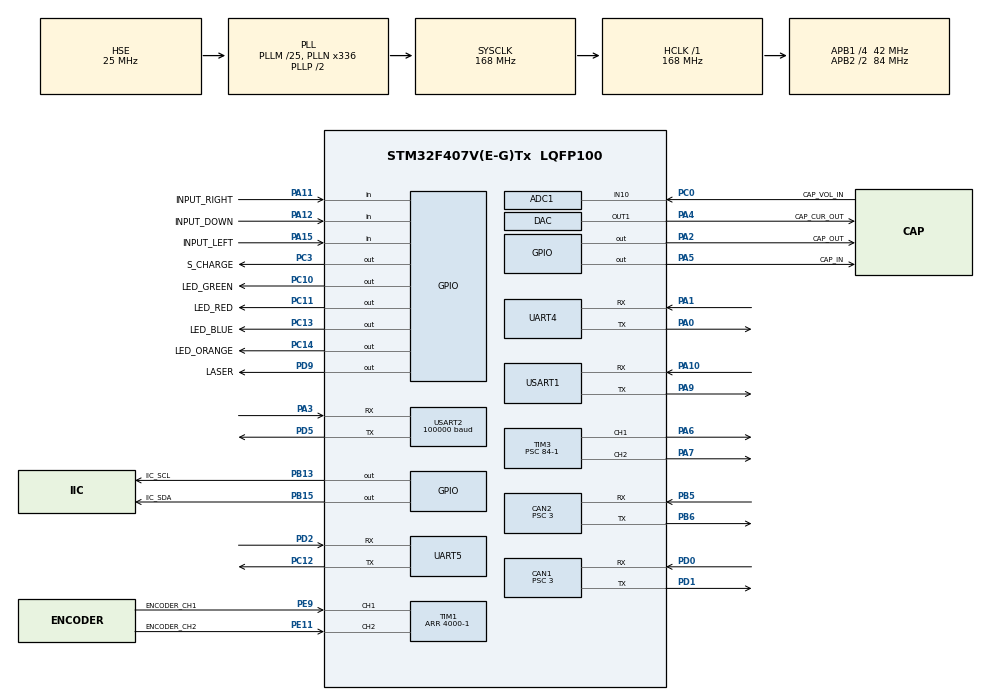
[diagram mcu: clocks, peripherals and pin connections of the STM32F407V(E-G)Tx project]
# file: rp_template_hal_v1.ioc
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ADC1.Channel-0\#ChannelRegularConversion=ADC_CHANNEL_10
ADC1.NbrOfConversionFlag=1
ADC1.Rank-0\#ChannelRegularConversion=1
ADC1.SamplingTime-0\#ChannelRegularConversion=ADC_SAMPLETIME_3CYCLES
ADC1.master=1
CAN1.ABOM=ENABLE
CAN1.AWUM=ENABLE
CAN1.BS1=CAN_BS1_9TQ
CAN1.BS2=CAN_BS2_4TQ
CAN1.CalculateBaudRate=1000000
CAN1.CalculateTimeBit=999.99
CAN1.CalculateTimeQuantum=71.42857142857143
CAN1.NART=ENABLE
CAN1.Prescaler=3
CAN1.TXFP=ENABLE
CAN2.ABOM=ENABLE
CAN2.AWUM=ENABLE
CAN2.BS1=CAN_BS1_9TQ
CAN2.BS2=CAN_BS2_4TQ
CAN2.CalculateBaudRate=1000000
CAN2.CalculateTimeBit=999.99
CAN2.CalculateTimeQuantum=71.42857142857143
CAN2.NART=ENABLE
CAN2.Prescaler=3
CAN2.TXFP=ENABLE
DAC.DAC_OutputBuffer=DAC_OUTPUTBUFFER_DISABLE
Dma.Request0=UART5_RX
Dma.Request1=USART1_RX
Dma.Request2=UART4_RX
Dma.Request3=USART2_RX
Dma.Request4=USART1_TX
Dma.Request5=UART4_TX
Dma.UART4_RX.2.Direction=DMA_PERIPH_TO_MEMORY
Dma.UART4_RX.2.FIFOMode=DMA_FIFOMODE_DISABLE
Dma.UART4_RX.2.Instance=DMA1_Stream2
Dma.UART4_RX.2.MemDataAlignment=DMA_MDATAALIGN_BYTE
Dma.UART4_RX.2.MemInc=DMA_MINC_ENABLE
Dma.UART4_RX.2.Mode=DMA_CIRCULAR
Dma.UART4_RX.2.PeriphDataAlignment=DMA_PDATAALIGN_BYTE
Dma.UART4_RX.2.PeriphInc=DMA_PINC_DISABLE
Dma.UART4_RX.2.Priority=DMA_PRIORITY_HIGH
Dma.UART4_TX.5.Direction=DMA_MEMORY_TO_PERIPH
Dma.UART4_TX.5.FIFOMode=DMA_FIFOMODE_DISABLE
Dma.UART4_TX.5.Instance=DMA1_Stream4
Dma.UART4_TX.5.MemDataAlignment=DMA_MDATAALIGN_BYTE
Dma.UART4_TX.5.MemInc=DMA_MINC_ENABLE
Dma.UART4_TX.5.Mode=DMA_NORMAL
Dma.UART4_TX.5.PeriphDataAlignment=DMA_PDATAALIGN_BYTE
Dma.UART4_TX.5.PeriphInc=DMA_PINC_DISABLE
Dma.UART4_TX.5.Priority=DMA_PRIORITY_HIGH
Dma.UART5_RX.0.Direction=DMA_PERIPH_TO_MEMORY
Dma.UART5_RX.0.FIFOMode=DMA_FIFOMODE_DISABLE
Dma.UART5_RX.0.Instance=DMA1_Stream0
Dma.UART5_RX.0.MemDataAlignment=DMA_MDATAALIGN_BYTE
Dma.UART5_RX.0.MemInc=DMA_MINC_ENABLE
Dma.UART5_RX.0.Mode=DMA_CIRCULAR
Dma.UART5_RX.0.PeriphDataAlignment=DMA_PDATAALIGN_BYTE
Dma.UART5_RX.0.PeriphInc=DMA_PINC_DISABLE
Dma.UART5_RX.0.Priority=DMA_PRIORITY_VERY_HIGH
Dma.USART1_RX.1.Direction=DMA_PERIPH_TO_MEMORY
Dma.USART1_RX.1.FIFOMode=DMA_FIFOMODE_DISABLE
Dma.USART1_RX.1.Instance=DMA2_Stream2
Dma.USART1_RX.1.MemDataAlignment=DMA_MDATAALIGN_BYTE
Dma.USART1_RX.1.MemInc=DMA_MINC_ENABLE
Dma.USART1_RX.1.Mode=DMA_CIRCULAR
Dma.USART1_RX.1.PeriphDataAlignment=DMA_PDATAALIGN_BYTE
Dma.USART1_RX.1.PeriphInc=DMA_PINC_DISABLE
Dma.USART1_RX.1.Priority=DMA_PRIORITY_HIGH
Dma.USART1_TX.4.Direction=DMA_MEMORY_TO_PERIPH
Dma.USART1_TX.4.FIFOMode=DMA_FIFOMODE_DISABLE
Dma.USART1_TX.4.Instance=DMA2_Stream7
Dma.USART1_TX.4.MemDataAlignment=DMA_MDATAALIGN_BYTE
Dma.USART1_TX.4.MemInc=DMA_MINC_ENABLE
Dma.USART1_TX.4.Mode=DMA_NORMAL
Dma.USART1_TX.4.PeriphDataAlignment=DMA_PDATAALIGN_BYTE
Dma.USART1_TX.4.PeriphInc=DMA_PINC_DISABLE
Dma.USART1_TX.4.Priority=DMA_PRIORITY_HIGH
Dma.USART2_RX.3.Direction=DMA_PERIPH_TO_MEMORY
Dma.USART2_RX.3.FIFOMode=DMA_FIFOMODE_DISABLE
Dma.USART2_RX.3.Instance=DMA1_Stream5
Dma.USART2_RX.3.MemDataAlignment=DMA_MDATAALIGN_BYTE
Dma.USART2_RX.3.MemInc=DMA_MINC_ENABLE
Dma.USART2_RX.3.Mode=DMA_CIRCULAR
Dma.USART2_RX.3.PeriphDataAlignment=DMA_PDATAALIGN_BYTE
Dma.USART2_RX.3.PeriphInc=DMA_PINC_DISABLE
Dma.USART2_RX.3.Priority=DMA_PRIORITY_VERY_HIGH
FREERTOS.Tasks01=MonitorTask,0,256,StartMonitorTask,As weak,NULL,Dynamic,NULL,NULL;SystemTask,0,128,StartSystemTask,As external,NULL,Dynamic,NULL,NULL;SendTask,-1,256,StartSendTask,As external,NULL,Dynamic,NULL,NULL;GimbalTask,2,256,StartGimbalTask,As external,NULL,Dynamic,NULL,NULL;ChassisTask,2,256,StartChassisTask,As external,NULL,Dynamic,NULL,NULL;FireTask,2,256,StartFireTask,As external,NULL,Dynamic,NULL,NULL;VisionTask,2,256,StartVisionTask,As external,NULL,Dynamic,NULL,NULL;ControlTask,2,256,StartControlTask,As external,NULL,Dynamic,NULL,NULL
IWDG.Prescaler=IWDG_PRESCALER_16
Mcu.Family=STM32F4
Mcu.Name=STM32F407V(E-G)Tx
Mcu.Package=LQFP100
NVIC.CAN1_RX0_IRQn=true\:5\:0\:true\:false\:true\:true\:true\:true
NVIC.CAN2_RX0_IRQn=true\:5\:0\:true\:false\:true\:true\:true\:true
NVIC.DMA1_Stream0_IRQn=true\:5\:0\:false\:false\:true\:true\:false\:true
NVIC.DMA1_Stream2_IRQn=true\:5\:0\:false\:false\:true\:true\:false\:true
NVIC.DMA1_Stream4_IRQn=true\:5\:0\:false\:false\:true\:true\:false\:true
NVIC.DMA1_Stream5_IRQn=true\:5\:0\:false\:false\:true\:true\:false\:true
NVIC.DMA2_Stream2_IRQn=true\:5\:0\:false\:false\:true\:true\:false\:true
NVIC.DMA2_Stream7_IRQn=true\:5\:0\:false\:false\:true\:true\:false\:true
NVIC.PriorityGroup=NVIC_PRIORITYGROUP_4
NVIC.TIM2_IRQn=true\:15\:0\:true\:false\:true\:false\:false\:true
NVIC.TimeBase=TIM2_IRQn
NVIC.TimeBaseIP=TIM2
NVIC.UART4_IRQn=true\:5\:0\:true\:false\:true\:true\:true\:true
NVIC.UART5_IRQn=true\:5\:0\:true\:false\:true\:true\:true\:true
NVIC.USART1_IRQn=true\:5\:0\:true\:false\:true\:true\:true\:true
NVIC.USART2_IRQn=true\:5\:0\:true\:false\:true\:true\:true\:true
PA0-WKUP.Mode=Asynchronous
PA0-WKUP.Signal=UART4_TX
PA1.Mode=Asynchronous
PA1.Signal=UART4_RX
PA10.Mode=Asynchronous
PA10.Signal=USART1_RX
PA11.GPIO_Label=INPUT_RIGHT
PA11.GPIO_PuPd=GPIO_PULLUP
PA11.Signal=GPIO_Input
PA12.GPIO_Label=INPUT_DOWN
PA12.GPIO_PuPd=GPIO_PULLUP
PA12.Signal=GPIO_Input
PA13.Mode=Serial_Wire
PA13.Signal=SYS_JTMS-SWDIO
PA14.Mode=Serial_Wire
PA14.Signal=SYS_JTCK-SWCLK
PA15.GPIO_Label=INPUT_LEFT
PA15.GPIO_PuPd=GPIO_PULLUP
PA15.Signal=GPIO_Input
PA2.GPIO_Label=CAP_OUT
PA2.GPIO_Speed=GPIO_SPEED_FREQ_VERY_HIGH
PA2.Signal=GPIO_Output
PA3.Mode=Asynchronous
PA3.Signal=USART2_RX
PA4.GPIO_Label=CAP_CUR_OUT
PA4.Signal=COMP_DAC1_group
PA5.GPIO_Label=CAP_IN
PA5.GPIO_Speed=GPIO_SPEED_FREQ_VERY_HIGH
PA5.Signal=GPIO_Output
PA6.Signal=S_TIM3_CH1
PA7.Signal=S_TIM3_CH2
PA9.Mode=Asynchronous
PA9.Signal=USART1_TX
PB13.GPIO_Label=IIC_SCL
PB13.GPIO_Speed=GPIO_SPEED_FREQ_VERY_HIGH
PB13.PinState=GPIO_PIN_SET
PB13.Signal=GPIO_Output
PB15.GPIO_Label=IIC_SDA
PB15.GPIO_Speed=GPIO_SPEED_FREQ_VERY_HIGH
PB15.PinState=GPIO_PIN_SET
PB15.Signal=GPIO_Output
PB5.Mode=CAN_Activate
PB5.Signal=CAN2_RX
PB6.Mode=CAN_Activate
PB6.Signal=CAN2_TX
PC0.GPIO_Label=CAP_VOL_IN
PC0.Signal=ADCx_IN10
PC10.GPIO_Label=LED_GREEN
PC10.GPIO_Speed=GPIO_SPEED_FREQ_LOW
PC10.PinState=GPIO_PIN_SET
PC10.Signal=GPIO_Output
PC11.GPIO_Label=LED_RED
PC11.GPIO_Speed=GPIO_SPEED_FREQ_LOW
PC11.PinState=GPIO_PIN_SET
PC11.Signal=GPIO_Output
PC12.Mode=Asynchronous
PC12.Signal=UART5_TX
PC13-ANTI_TAMP.GPIO_Label=LED_BLUE
PC13-ANTI_TAMP.PinState=GPIO_PIN_SET
PC13-ANTI_TAMP.Signal=GPIO_Output
PC14-OSC32_IN.GPIO_Label=LED_ORANGE
PC14-OSC32_IN.PinState=GPIO_PIN_SET
PC14-OSC32_IN.Signal=GPIO_Output
PC3.GPIO_Label=S_CHARGE
PC3.GPIO_Speed=GPIO_SPEED_FREQ_VERY_HIGH
PC3.Signal=GPIO_Output
PD0.Mode=CAN_Activate
PD0.Signal=CAN1_RX
PD1.Mode=CAN_Activate
PD1.Signal=CAN1_TX
PD2.Mode=Asynchronous
PD2.Signal=UART5_RX
PD5.Mode=Asynchronous
PD5.Signal=USART2_TX
PD9.GPIO_Label=LASER
PD9.GPIO_Speed=GPIO_SPEED_FREQ_LOW
PD9.PinState=GPIO_PIN_SET
PD9.Signal=GPIO_Output
PE11.GPIO_Label=ENCODER_CH2
PE11.GPIO_ModeDefaultPP=GPIO_MODE_AF_OD
PE11.GPIO_PuPd=GPIO_PULLUP
PE11.Signal=S_TIM1_CH2
PE9.GPIO_Label=ENCODER_CH1
PE9.GPIO_ModeDefaultPP=GPIO_MODE_AF_OD
PE9.GPIO_PuPd=GPIO_PULLUP
PE9.Signal=S_TIM1_CH1
PH0-OSC_IN.Mode=HSE-External-Oscillator
PH0-OSC_IN.Signal=RCC_OSC_IN
PH1-OSC_OUT.Mode=HSE-External-Oscillator
PH1-OSC_OUT.Signal=RCC_OSC_OUT
ProjectManager.HeapSize=0x200
ProjectManager.StackSize=0x400
ProjectManager.TargetToolchain=MDK-ARM V5.27
RCC.48MHZClocksFreq_Value=84000000
RCC.AHBFreq_Value=168000000
RCC.APB1CLKDivider=RCC_HCLK_DIV4
RCC.APB1Freq_Value=42000000
RCC.APB1TimFreq_Value=84000000
RCC.APB2CLKDivider=RCC_HCLK_DIV2
RCC.APB2Freq_Value=84000000
RCC.APB2TimFreq_Value=168000000
RCC.CortexFreq_Value=168000000
RCC.HCLKFreq_Value=168000000
RCC.HSE_VALUE=25000000
RCC.HSI_VALUE=16000000
RCC.LSE_VALUE=32768
RCC.PLLM=25
RCC.PLLN=336
RCC.PLLSourceVirtual=RCC_PLLSOURCE_HSE
RCC.SYSCLKFreq_VALUE=168000000
RCC.SYSCLKSource=RCC_SYSCLKSOURCE_PLLCLK
RCC.VCOOutputFreq_Value=336000000
SH.ADCx_IN10.0=ADC1_IN10,IN10
SH.COMP_DAC1_group.0=DAC_OUT1,DAC_OUT1
SH.S_TIM1_CH1.0=TIM1_CH1,Encoder_Interface
SH.S_TIM1_CH2.0=TIM1_CH2,Encoder_Interface
SH.S_TIM3_CH1.0=TIM3_CH1,PWM Generation1 CH1
SH.S_TIM3_CH2.0=TIM3_CH2,PWM Generation2 CH2
TIM1.EncoderMode=TIM_ENCODERMODE_TI12
TIM1.Period=4000-1
TIM3.Channel-PWM\ Generation1\ CH1=TIM_CHANNEL_1
TIM3.Channel-PWM\ Generation2\ CH2=TIM_CHANNEL_2
TIM3.Period=2500-1
TIM3.Prescaler=84-1
UART4.VirtualMode=Asynchronous
UART5.VirtualMode=Asynchronous
USART1.VirtualMode=VM_ASYNC
USART2.BaudRate=100000
USART2.VirtualMode=VM_ASYNC
VP_FREERTOS_VS_CMSIS_V1.Mode=CMSIS_V1
VP_IWDG_VS_IWDG.Mode=IWDG_Activate
VP_SYS_VS_tim2.Mode=TIM2
VP_TIM3_VS_ClockSourceINT.Mode=Internal
board=custom

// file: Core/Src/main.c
/* USER CODE BEGIN Header */
/**
  ******************************************************************************
  * @file           : main.c
  * @brief          : Main program body
  ******************************************************************************
  * @attention
  *
  * <h2><center>&copy; Copyright (c) 2020 STMicroelectronics.
  * All rights reserved.</center></h2>
  *
  * This software component is licensed by ST under Ultimate Liberty license
  * SLA0044, the "License"; You may not use this file except in compliance with
  * the License. You may obtain a copy of the License at:
  *                             www.st.com/SLA0044
  *
  ******************************************************************************
  */
/* USER CODE END Header */
#include "main.h"
#include "cmsis_os.h"
#include "adc.h"
#include "can.h"
#include "dac.h"
#include "dma.h"
#include "iwdg.h"
#include "tim.h"
#include "usart.h"
#include "gpio.h"

/* USER CODE BEGIN Includes */
#include "driver.h"
#include "device.h"
/* USER CODE END Includes */

void SystemClock_Config(void);
void MX_FREERTOS_Init(void);

int main(void)
{

  /* MCU Configuration--------------------------------------------------------*/

  /* Reset of all peripherals, Initializes the Flash interface and the Systick. */
  HAL_Init();

  /* Configure the system clock */
  SystemClock_Config();

  /* Initialize all configured peripherals */
  MX_GPIO_Init();
  MX_DMA_Init();
  MX_TIM3_Init();
  MX_USART2_UART_Init();
  MX_CAN1_Init();
  MX_CAN2_Init();
  MX_TIM1_Init();
  MX_ADC1_Init();
  MX_DAC_Init();
  MX_UART4_Init();
  MX_UART5_Init();
  MX_USART1_UART_Init();
  MX_IWDG_Init();
  /* USER CODE BEGIN 2 */
    // �������ʼ��
	DRIVER_Init();
	// �豸���ʼ��
	DEV_Init();
//    while(1) {
//        delay_ms(1000);
//        LED_RED_TOGGLE();
//    }
  /* USER CODE END 2 */

  /* Call init function for freertos objects (in freertos.c) */
  MX_FREERTOS_Init();
  /* Start scheduler */
  osKernelStart();

  /* We should never get here as control is now taken by the scheduler */
  /* Infinite loop */
  while (1)
  {

  }
}

void SystemClock_Config(void)
{
  RCC_OscInitTypeDef RCC_OscInitStruct = {0};
  RCC_ClkInitTypeDef RCC_ClkInitStruct = {0};

  /** Configure the main internal regulator output voltage
  */
  __HAL_RCC_PWR_CLK_ENABLE();
  __HAL_PWR_VOLTAGESCALING_CONFIG(PWR_REGULATOR_VOLTAGE_SCALE1);
  /** Initializes the RCC Oscillators according to the specified parameters
  * in the RCC_OscInitTypeDef structure.
  */
  RCC_OscInitStruct.OscillatorType = RCC_OSCILLATORTYPE_LSI|RCC_OSCILLATORTYPE_HSE;
  RCC_OscInitStruct.HSEState = RCC_HSE_ON;
  RCC_OscInitStruct.LSIState = RCC_LSI_ON;
  RCC_OscInitStruct.PLL.PLLState = RCC_PLL_ON;
  RCC_OscInitStruct.PLL.PLLSource = RCC_PLLSOURCE_HSE;
  RCC_OscInitStruct.PLL.PLLM = 25;
  RCC_OscInitStruct.PLL.PLLN = 336;
  RCC_OscInitStruct.PLL.PLLP = RCC_PLLP_DIV2;
  RCC_OscInitStruct.PLL.PLLQ = 4;
  if (HAL_RCC_OscConfig(&RCC_OscInitStruct) != HAL_OK)
  {
    Error_Handler();
  }
  /** Initializes the CPU, AHB and APB buses clocks
  */
  RCC_ClkInitStruct.ClockType = RCC_CLOCKTYPE_HCLK|RCC_CLOCKTYPE_SYSCLK
                              |RCC_CLOCKTYPE_PCLK1|RCC_CLOCKTYPE_PCLK2;
  RCC_ClkInitStruct.SYSCLKSource = RCC_SYSCLKSOURCE_PLLCLK;
  RCC_ClkInitStruct.AHBCLKDivider = RCC_SYSCLK_DIV1;
  RCC_ClkInitStruct.APB1CLKDivider = RCC_HCLK_DIV4;
  RCC_ClkInitStruct.APB2CLKDivider = RCC_HCLK_DIV2;

  if (HAL_RCC_ClockConfig(&RCC_ClkInitStruct, FLASH_LATENCY_5) != HAL_OK)
  {
    Error_Handler();
  }
}

void HAL_TIM_PeriodElapsedCallback(TIM_HandleTypeDef *htim)
{
  if (htim->Instance == TIM2) {
    HAL_IncTick();
  }
}

void Error_Handler(void)
{
}

/************************ (C) COPYRIGHT STMicroelectronics *****END OF FILE****/

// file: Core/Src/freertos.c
/* USER CODE BEGIN Header */
/**
  ******************************************************************************
  * File Name          : freertos.c
  * Description        : Code for freertos applications
  ******************************************************************************
  * @attention
  *
  * <h2><center>&copy; Copyright (c) 2020 STMicroelectronics.
  * All rights reserved.</center></h2>
  *
  * This software component is licensed by ST under Ultimate Liberty license
  * SLA0044, the "License"; You may not use this file except in compliance with
  * the License. You may obtain a copy of the License at:
  *                             www.st.com/SLA0044
  *
  ******************************************************************************
  */
/* USER CODE END Header */

#include "FreeRTOS.h"
#include "task.h"
#include "main.h"
#include "cmsis_os.h"

osThreadId MonitorTaskHandle;
osThreadId SystemTaskHandle;
osThreadId SendTaskHandle;
osThreadId GimbalTaskHandle;
osThreadId ChassisTaskHandle;
osThreadId FireTaskHandle;
osThreadId VisionTaskHandle;
osThreadId ControlTaskHandle;

void StartMonitorTask(void const * argument);
extern void StartSystemTask(void const * argument);
extern void StartSendTask(void const * argument);
extern void StartGimbalTask(void const * argument);
extern void StartChassisTask(void const * argument);
extern void StartFireTask(void const * argument);
extern void StartVisionTask(void const * argument);
extern void StartControlTask(void const * argument);

void MX_FREERTOS_Init(void); /* (MISRA C 2004 rule 8.1) */

/* GetIdleTaskMemory prototype (linked to static allocation support) */
void vApplicationGetIdleTaskMemory( StaticTask_t **ppxIdleTaskTCBBuffer, StackType_t **ppxIdleTaskStackBuffer, uint32_t *pulIdleTaskStackSize );

/* USER CODE BEGIN GET_IDLE_TASK_MEMORY */
static StaticTask_t xIdleTaskTCBBuffer;
static StackType_t xIdleStack[configMINIMAL_STACK_SIZE];

void vApplicationGetIdleTaskMemory( StaticTask_t **ppxIdleTaskTCBBuffer, StackType_t **ppxIdleTaskStackBuffer, uint32_t *pulIdleTaskStackSize )
{
  *ppxIdleTaskTCBBuffer = &xIdleTaskTCBBuffer;
  *ppxIdleTaskStackBuffer = &xIdleStack[0];
  *pulIdleTaskStackSize = configMINIMAL_STACK_SIZE;
  /* place for user code */
}
/* USER CODE END GET_IDLE_TASK_MEMORY */

void MX_FREERTOS_Init(void) {

  /* Create the thread(s) */
  /* definition and creation of MonitorTask */
  osThreadDef(MonitorTask, StartMonitorTask, osPriorityNormal, 0, 256);
  MonitorTaskHandle = osThreadCreate(osThread(MonitorTask), NULL);

  /* definition and creation of SystemTask */
  osThreadDef(SystemTask, StartSystemTask, osPriorityNormal, 0, 128);
  SystemTaskHandle = osThreadCreate(osThread(SystemTask), NULL);

  /* definition and creation of SendTask */
  osThreadDef(SendTask, StartSendTask, osPriorityBelowNormal, 0, 256);
  SendTaskHandle = osThreadCreate(osThread(SendTask), NULL);

  /* definition and creation of GimbalTask */
  osThreadDef(GimbalTask, StartGimbalTask, osPriorityHigh, 0, 256);
  GimbalTaskHandle = osThreadCreate(osThread(GimbalTask), NULL);

  /* definition and creation of ChassisTask */
  osThreadDef(ChassisTask, StartChassisTask, osPriorityHigh, 0, 256);
  ChassisTaskHandle = osThreadCreate(osThread(ChassisTask), NULL);

  /* definition and creation of FireTask */
  osThreadDef(FireTask, StartFireTask, osPriorityHigh, 0, 256);
  FireTaskHandle = osThreadCreate(osThread(FireTask), NULL);

  /* definition and creation of VisionTask */
  osThreadDef(VisionTask, StartVisionTask, osPriorityHigh, 0, 256);
  VisionTaskHandle = osThreadCreate(osThread(VisionTask), NULL);

  /* definition and creation of ControlTask */
  osThreadDef(ControlTask, StartControlTask, osPriorityHigh, 0, 256);
  ControlTaskHandle = osThreadCreate(osThread(ControlTask), NULL);

}

__weak void StartMonitorTask(void const * argument)
{
  for(;;)
  {
    osDelay(1);
  }
}

/************************ (C) COPYRIGHT STMicroelectronics *****END OF FILE****/
